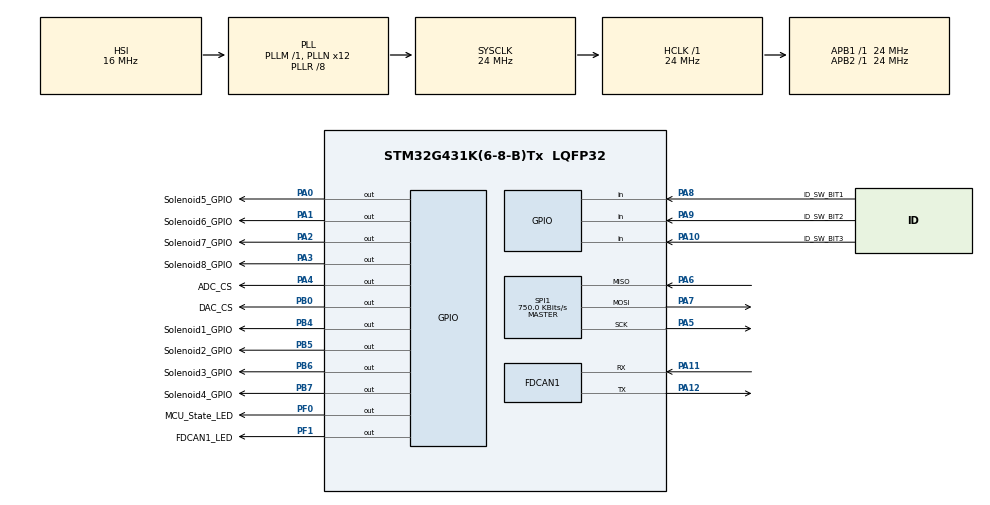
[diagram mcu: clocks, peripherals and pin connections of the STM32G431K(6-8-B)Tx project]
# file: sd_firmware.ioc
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FDCAN1.CalculateBaudRateNominal=1000000
FDCAN1.CalculateTimeBitNominal=1000
FDCAN1.CalculateTimeQuantumNominal=125.0
FDCAN1.DataPrescaler=1
FDCAN1.DataTimeSeg1=1
FDCAN1.DataTimeSeg2=1
FDCAN1.NominalPrescaler=3
FDCAN1.NominalTimeSeg1=6
FDCAN1.StdFiltersNbr=3
Mcu.Family=STM32G4
Mcu.Name=STM32G431K(6-8-B)Tx
Mcu.Package=LQFP32
NVIC.FDCAN1_IT0_IRQn=true\:0\:0\:false\:false\:true\:true\:true\:true
NVIC.FDCAN1_IT1_IRQn=true\:0\:0\:false\:false\:true\:true\:true\:true
NVIC.PriorityGroup=NVIC_PRIORITYGROUP_4
NVIC.TIM1_UP_TIM16_IRQn=true\:0\:0\:false\:false\:true\:true\:true\:true
PA0.GPIO_Label=Solenoid5_GPIO
PA0.Signal=GPIO_Output
PA1.GPIO_Label=Solenoid6_GPIO
PA1.Signal=GPIO_Output
PA10.GPIO_Label=ID_SW_BIT3
PA10.Signal=GPIO_Input
PA11.Mode=FDCAN_Activate
PA11.Signal=FDCAN1_RX
PA12.Mode=FDCAN_Activate
PA12.Signal=FDCAN1_TX
PA13.Mode=Trace_Asynchronous_SW
PA13.Signal=SYS_JTMS-SWDIO
PA14.Mode=Trace_Asynchronous_SW
PA14.Signal=SYS_JTCK-SWCLK
PA2.GPIO_Label=Solenoid7_GPIO
PA2.Signal=GPIO_Output
PA3.GPIO_Label=Solenoid8_GPIO
PA3.Signal=GPIO_Output
PA4.GPIO_Label=ADC_CS
PA4.PinState=GPIO_PIN_SET
PA4.Signal=GPIO_Output
PA5.Mode=Full_Duplex_Master
PA5.Signal=SPI1_SCK
PA6.Mode=Full_Duplex_Master
PA6.Signal=SPI1_MISO
PA7.Mode=Full_Duplex_Master
PA7.Signal=SPI1_MOSI
PA8.GPIO_Label=ID_SW_BIT1
PA8.Signal=GPIO_Input
PA9.GPIO_Label=ID_SW_BIT2
PA9.Signal=GPIO_Input
PB0.GPIO_Label=DAC_CS
PB0.PinState=GPIO_PIN_SET
PB0.Signal=GPIO_Output
PB3.Mode=Trace_Asynchronous_SW
PB3.Signal=SYS_JTDO-SWO
PB4.GPIO_Label=Solenoid1_GPIO
PB4.Signal=GPIO_Output
PB5.GPIO_Label=Solenoid2_GPIO
PB5.Signal=GPIO_Output
PB6.GPIO_Label=Solenoid3_GPIO
PB6.Signal=GPIO_Output
PB7.GPIO_Label=Solenoid4_GPIO
PB7.Signal=GPIO_Output
PF0-OSC_IN.GPIO_Label=MCU_State_LED
PF0-OSC_IN.Signal=GPIO_Output
PF1-OSC_OUT.GPIO_Label=FDCAN1_LED
PF1-OSC_OUT.Signal=GPIO_Output
ProjectManager.HeapSize=0x200
ProjectManager.StackSize=0x400
ProjectManager.TargetToolchain=CMake
RCC.ADC12Freq_Value=24000000
RCC.AHBFreq_Value=24000000
RCC.APB1Freq_Value=24000000
RCC.APB1TimFreq_Value=24000000
RCC.APB2Freq_Value=24000000
RCC.APB2TimFreq_Value=24000000
RCC.CortexFreq_Value=24000000
RCC.EXTERNAL_CLOCK_VALUE=12288000
RCC.HCLKFreq_Value=24000000
RCC.HSE_VALUE=8000000
RCC.HSI48_VALUE=48000000
RCC.HSI_VALUE=16000000
RCC.LSE_VALUE=32768
RCC.PLLN=12
RCC.PLLR=RCC_PLLR_DIV8
RCC.SYSCLKFreq_VALUE=24000000
RCC.SYSCLKSource=RCC_SYSCLKSOURCE_PLLCLK
RCC.USBFreq_Value=96000000
RCC.VCOOutputFreq_Value=192000000
SPI1.BaudRatePrescaler=SPI_BAUDRATEPRESCALER_32
SPI1.CLKPhase=SPI_PHASE_2EDGE
SPI1.CalculateBaudRate=750.0 KBits/s
SPI1.DataSize=SPI_DATASIZE_8BIT
SPI1.Direction=SPI_DIRECTION_2LINES
SPI1.Mode=SPI_MODE_MASTER
SPI1.VirtualType=VM_MASTER
TIM16.Prescaler=15
VP_SYS_VS_DBSignals.Mode=DisableDeadBatterySignals
VP_TIM16_VS_ClockSourceINT.Mode=Enable_Timer
board=custom

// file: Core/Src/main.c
/* USER CODE BEGIN Header */
/**
  ******************************************************************************
  * @file           : main.c
  * @brief          : Main program body
  ******************************************************************************
  * @attention
  *
  * Copyright (c) 2026 STMicroelectronics.
  * All rights reserved.
  *
  * This software is licensed under terms that can be found in the LICENSE file
  * in the root directory of this software component.
  * If no LICENSE file comes with this software, it is provided AS-IS.
  *
  ******************************************************************************
  */
/* USER CODE END Header */
#include "main.h"
#include "fdcan.h"
#include "spi.h"
#include "tim.h"
#include "gpio.h"

/* USER CODE BEGIN Includes */
float_mpa target_value;
/* USER CODE END Includes */

void SystemClock_Config(void);

int main(void)
{

  /* MCU Configuration--------------------------------------------------------*/

  /* Reset of all peripherals, Initializes the Flash interface and the Systick. */
  HAL_Init();

  /* Configure the system clock */
  SystemClock_Config();

  /* Initialize all configured peripherals */
  MX_GPIO_Init();
  MX_FDCAN1_Init();
  MX_TIM16_Init();
  MX_SPI1_Init();
  /* USER CODE BEGIN 2 */
  HAL_TIM_Base_Start_IT(&htim16); // タイマー割り込み開始

  dac_init(0);
  HAL_GPIO_WritePin(MCU_State_LED_GPIO_Port, MCU_State_LED_Pin, GPIO_PIN_RESET);
  HAL_GPIO_WritePin(FDCAN1_LED_GPIO_Port, FDCAN1_LED_Pin, GPIO_PIN_RESET);
  /* USER CODE END 2 */

  /* Infinite loop */
  /* USER CODE BEGIN WHILE */
  while (1)
  {
    // dac_init(target_value.value);
    dac_set_MPa(target_value.value);
    HAL_Delay(100);
    /* USER CODE END WHILE */

  }
}

void SystemClock_Config(void)
{
  RCC_OscInitTypeDef RCC_OscInitStruct = {0};
  RCC_ClkInitTypeDef RCC_ClkInitStruct = {0};

  /** Configure the main internal regulator output voltage
  */
  HAL_PWREx_ControlVoltageScaling(PWR_REGULATOR_VOLTAGE_SCALE1);

  /** Initializes the RCC Oscillators according to the specified parameters
  * in the RCC_OscInitTypeDef structure.
  */
  RCC_OscInitStruct.OscillatorType = RCC_OSCILLATORTYPE_HSI;
  RCC_OscInitStruct.HSIState = RCC_HSI_ON;
  RCC_OscInitStruct.HSICalibrationValue = RCC_HSICALIBRATION_DEFAULT;
  RCC_OscInitStruct.PLL.PLLState = RCC_PLL_ON;
  RCC_OscInitStruct.PLL.PLLSource = RCC_PLLSOURCE_HSI;
  RCC_OscInitStruct.PLL.PLLM = RCC_PLLM_DIV1;
  RCC_OscInitStruct.PLL.PLLN = 12;
  RCC_OscInitStruct.PLL.PLLP = RCC_PLLP_DIV2;
  RCC_OscInitStruct.PLL.PLLQ = RCC_PLLQ_DIV2;
  RCC_OscInitStruct.PLL.PLLR = RCC_PLLR_DIV8;
  if (HAL_RCC_OscConfig(&RCC_OscInitStruct) != HAL_OK)
  {
    Error_Handler();
  }

  /** Initializes the CPU, AHB and APB buses clocks
  */
  RCC_ClkInitStruct.ClockType = RCC_CLOCKTYPE_HCLK|RCC_CLOCKTYPE_SYSCLK
                              |RCC_CLOCKTYPE_PCLK1|RCC_CLOCKTYPE_PCLK2;
  RCC_ClkInitStruct.SYSCLKSource = RCC_SYSCLKSOURCE_PLLCLK;
  RCC_ClkInitStruct.AHBCLKDivider = RCC_SYSCLK_DIV1;
  RCC_ClkInitStruct.APB1CLKDivider = RCC_HCLK_DIV1;
  RCC_ClkInitStruct.APB2CLKDivider = RCC_HCLK_DIV1;

  if (HAL_RCC_ClockConfig(&RCC_ClkInitStruct, FLASH_LATENCY_0) != HAL_OK)
  {
    Error_Handler();
  }
}

/* USER CODE BEGIN 4 */
//タイマーの周期ごとに自動で呼ばれる割り込み関数
void HAL_TIM_PeriodElapsedCallback(TIM_HandleTypeDef *htim){
  if (htim->Instance == TIM16){
  //最新のバッファ状態をGPIOへ一括反映
    updateSolenoidOutputs();
  }
}

/* USER CODE END 4 */

void Error_Handler(void)
{
  __disable_irq();
  while (1)
  {
  }
}
